AUTOSAR XML (schema 00046)
package /Composition_Interface_Lab
  sender receiver interface SRI_LightControl
    data lightControl: type=uint16
  sender receiver interface SRI_LightActuate
    data lightActuate: type=uint16
  sensor actuator sw component type LightControlStatus_SWC
    provide port SR_LIGHTCONTROL: provided-interface=SRI_LightActuate
  sensor actuator sw component type LightActuator_SWC
    require port SR_LIGHTACTUATE: required-interface=lightControl
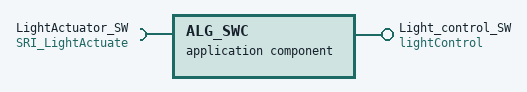
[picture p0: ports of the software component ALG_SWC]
  application sw component type ALG_SWC
    provide port Light_control_SW: provided-interface=lightControl
    require port LightActuator_SW: required-interface=SRI_LightActuate
